# MPU_CM_CORE_AON register map
Vendor: Texas Instruments
Peripheral module from a debugger description file (folder omap5430_ES2_PUBLIC).
Registers are 32-bit, access per field, reset 0x0 unless marked. A register's access mark holds for its fields unless they carry their own. Offsets are as the file gives them; lines under a group give offsets from that group; [hi:lo] are bit positions; {n}, {i} and the like mark numbered series; 'fields as' and 'values as' point back to an identical list; <NAME> marks a mode.

## MPU_CM_CORE_AON
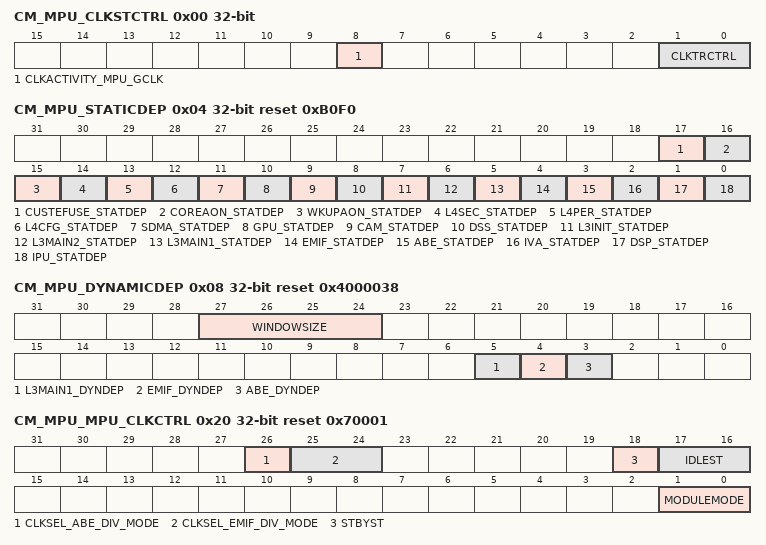
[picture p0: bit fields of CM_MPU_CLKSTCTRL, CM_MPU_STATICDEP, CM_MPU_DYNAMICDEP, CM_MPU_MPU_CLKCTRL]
0x00 CM_MPU_CLKSTCTRL — This register enables the MPU domain power state transition. It controls the HW supervised domain power state transition between ON-ACTIVE and ON-INACTIVE states. It also holds 1 status bit per clock input of the domain.
  [8] CLKACTIVITY_MPU_GCLK ro — This field indicates the state of the MPU_GCLK clock in the domain. [warm reset insensitive]
    0=Inact (Corresponding clock is definitely gated); 1=Act (Corresponding clock is running or gating/ungating transition is on-going)
  [1:0] CLKTRCTRL rw — Controls the clock state transition of the MPU clock domain.
    0=NO_SLEEP (NO_SLEEP: Sleep transition cannot be initiated. Wakeup transition may however occur.); 2=SW_WKUP (SW_WKUP: Start a software forced wake-up transition on the domain.); 3=HW_AUTO (HW_AUTO: Automatic transition is enabled. Sleep and wakeup transition are based upon hardware conditions.)
0x04 CM_MPU_STATICDEP reset 0xB0F0 — This register controls the static domain dependencies from MPU domain towards 'target' domains. It is relevant only for domain having system initiator(s).
  [17] CUSTEFUSE_STATDEP ro — Static dependency towards CUSTEFUSE clock domain
    0=Dependency_is_disabled
  [16] COREAON_STATDEP ro — Static dependency towards COREAON clock domain
    0=Disabled (Dependency is disabled)
  [15] WKUPAON_STATDEP rw — Static dependency towards WKUPAON clock domain
    0=Disabled (Dependency is disabled); 1=Enabled (Dependency is enabled)
  [14] L4SEC_STATDEP rw — Static dependency towards L4SEC clock domain
    0=Dependency_is_disabled; 1=Dependency_is_enabled
  [13] L4PER_STATDEP rw — Static dependency towards L4_PER clock domain
    values as WKUPAON_STATDEP
  [12] L4CFG_STATDEP rw — Static dependency towards L4_CFG clock domain
    values as WKUPAON_STATDEP
  [11] SDMA_STATDEP ro — Static dependency towards DMA_SYSTEM clock domain
    0=Disabled (Dependency is disabled)
  [10] GPU_STATDEP rw — Static dependency towards GPU clock domain
    values as WKUPAON_STATDEP
  [9] CAM_STATDEP ro — Static dependency towards CAM clock domain
    0=Disabled (Dependency is disabled)
  [8] DSS_STATDEP rw — Static dependency towards DSS clock domain
    values as WKUPAON_STATDEP
  [7] L3INIT_STATDEP rw — Static dependency towards L3INIT clock domain
    values as WKUPAON_STATDEP
  [6] L3MAIN2_STATDEP rw — Static dependency towards L3_MAIN2 clock domain
    values as WKUPAON_STATDEP
  [5] L3MAIN1_STATDEP rw — Static dependency towards L3_MAIN1 clock domain
    values as WKUPAON_STATDEP
  [4] EMIF_STATDEP rw — Static dependency towards EMIF clock domain
    values as WKUPAON_STATDEP
  [3] ABE_STATDEP rw — Static dependency towards ABE clock domain
    values as WKUPAON_STATDEP
  [2] IVA_STATDEP rw — Static dependency towards IVA clock domain
    values as WKUPAON_STATDEP
  [1] DSP_STATDEP rw — Static dependency towards DSP clock domain
    values as WKUPAON_STATDEP
  [0] IPU_STATDEP rw — Static dependency towards IPU clock domain
    values as WKUPAON_STATDEP
0x08 CM_MPU_DYNAMICDEP reset 0x4000038 — This register controls the dynamic domain depedencies from MPU domain towards 'target' domains. It is relevant only for domain having INTRCONN master port(s).
  [27:24] WINDOWSIZE rw — Size of sliding window used to monitor INTRCONN interface activity for determination of auto-sleep feature. Time unit defined byCM_DYN_DEP_PRESCAL register.
  [5] L3MAIN1_DYNDEP ro — Dynamic dependency towards L3_MAIN1 clock domain
    1=Enabled (Dependency is enabled)
  [4] EMIF_DYNDEP ro — Dynamic dependency towards EMIF clock domain
    1=Enabled (Dependency is enabled)
  [3] ABE_DYNDEP ro — Dynamic dependency towards ABE clock domain
    1=Enabled (Dependency is enabled)
0x20 CM_MPU_MPU_CLKCTRL reset 0x70001 — This register manages the MPU clocks.
  [26] CLKSEL_ABE_DIV_MODE rw — Selects the ratio for MPU - ABE Subsystem bridge versus MPU DPLL clock 0x0: MPU DPLL clock divided by 8 0x1: MPU DPLL clock divided by 16
  [25:24] CLKSEL_EMIF_DIV_MODE rw — Selects the ratio for MPU - L3_MAIN interconnect bridge versus MPU DPLL clock. 0x0: MPU DPLL clock divided by 4 0x1: MPU DPLL clock divided by 4 0x2: MPU DPLL clock divided by 8 0x3: MPU DPLL clock divided by 8
  [18] STBYST ro — Module standby status. [warm reset insensitive]
    0=Func (Module is functional (not in standby)); 1=Standby (Module is in standby)
  [17:16] IDLEST ro — Module idle status. [warm reset insensitive]
    0=Func (Module is fully functional, including INTRCONN); 1=Trans (Module is performing transition: wakeup, or sleep, or sleep abortion); 2=Idle (Module is in Idle mode (only INTRCONN part). It is functional if using separate functional clock); 3=Disable (Module is disabled and cannot be accessed)
  [1:0] MODULEMODE ro — Control the way mandatory clocks are managed.
    1=AUTO (Module is managed automatically by HW according to clock domain transition. A clock domain sleep transition put module into idle. A wakeup domain transition put it back into function. Module clocks may be gated according to the clock domain state.)
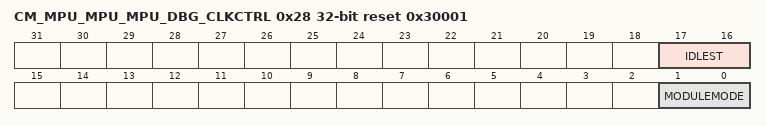
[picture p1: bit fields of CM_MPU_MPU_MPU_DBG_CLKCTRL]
0x28 CM_MPU_MPU_MPU_DBG_CLKCTRL access not given reset 0x30001 — This register manages the MPU_MPU_DBG clocks. [warm reset insensitive]
  [17:16] IDLEST ro — Module idle status
    3=Disable (Module is disabled and cannot be accessed); 2=Idle (Module is in Idle mode (only OCP part). It is functional if using separate functional clock); 1=Trans (Module is performing transition: wakeup, or sleep, or sleep abortion); 0=Func (Module is fully functional, including OCP)
  [1:0] MODULEMODE — Control the way mandatory clocks are managed. (access R Rreturns)
    1=AUTO (Module is managed automatically by HW according to clock domain transition. A clock domain sleep transition put module into idle. A wakeup domain transition put it back into function. If CLKTRCTRL=3, any OCP access to module is always granted. Module clocks may be gated according to the clock domain state.)
